# STM32U083xx register map
File version: 1.0
Registers are 32-bit, read-write, reset 0x0 unless marked. A register's access mark holds for its fields unless they carry their own. Offsets are from the block's base; [hi:lo] are bit positions; {n}, {i} and the like mark numbered series.

## OPAMP1 — Operational Amplifier (OPAMP)
Base 0x40007800
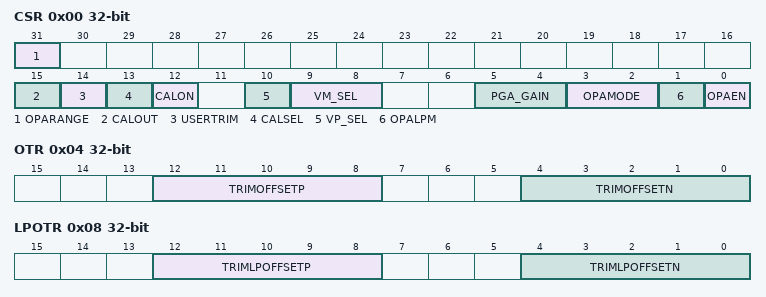
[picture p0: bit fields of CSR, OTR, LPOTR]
0x00 CSR — OPAMP control/status register
  [31] OPARANGE — Operational amplifier range setting
    0=LOW (Power supply range low); 1=HIGH (Power supply range high - recommended for performance purpose)
  [15] CALOUT — Operational amplifier calibration output
  [14] USERTRIM — User trimming enable
    0=FACTORY (OPAMP trimming factors set to factory values); 1=USER (OPAMP trimming factors set to user values)
  [13] CALSEL — Calibration selection
  [12] CALON — Calibration mode enable
    0=FUNCTIONAL (OPAMP functional mode); 1=CALIBRATION (OPAMP calibration mode)
  [10] VP_SEL — Non inverted input selection
    0=NONINVERT_IO0 (OPAMP non inverting input connected to GPIO pin (pin PA0 for OPAMP1)); 1=NONINV_DAC1_CH1 (OPAMP non inverting input connected to DAC1 channel output(channel1 for OPAMP1))
  [9:8] VM_SEL — Inverting input selection
    0=IO0 (OPAMP inverting input connected to GPIO pin (valid also in PGA mode for filtering). Note: OPAMP inverting input is used with OPAMP in mode standalone or PGA with external capacitors for filtering circuit. Otherwise (OPAMP in mode follower), OPAMP inverting input is not used (not connected to GPIO pin).); 2=CONNECT_NO (OPAMP inverting input not externally connected (intended for OPAMP in mode follower or PGA without external capacitors for filtering))
  [5:4] PGA_GAIN — Operational amplifier Programmable amplifier gain value
    0=GAIN_2 (OPAMP PGA gain 2); 1=GAIN_4 (OPAMP PGA gain 4); 2=GAIN_8 (OPAMP PGA gain 8); 3=GAIN_16 (OPAMP PGA gain 16)
  [3:2] OPAMODE — Operational amplifier PGA mode
    0=STANDALONE (OPAMP functional mode, OPAMP operation in standalone); 3=FOLLOWER (OPAMP functional mode, OPAMP operation in follower); 2=PGA (OPAMP functional mode, OPAMP operation in PGA)
  [1] OPALPM — Operational amplifier Low Power Mode
  [0] OPAEN — OPAMP enable
0x04 OTR — OPAMP
  [12:8] TRIMOFFSETP — Trim for PMOS differential pairs
  [4:0] TRIMOFFSETN — Trim for NMOS differential pairs
0x08 LPOTR — OPAMP
  [12:8] TRIMLPOFFSETP — Trim for PMOS differential pairs
  [4:0] TRIMLPOFFSETN — Trim for NMOS differential pairs

## USB_DRD_PMA_BUFF — Universal Serial Bus PacketMemoryArea Buffer Descriptor Table
Base 0x40009800
0x00 TXBD — Transmission buffer address
0x04 RXBD — Reception buffer address

## TAMP — Tamper and backup registers
Base 0x4000B000
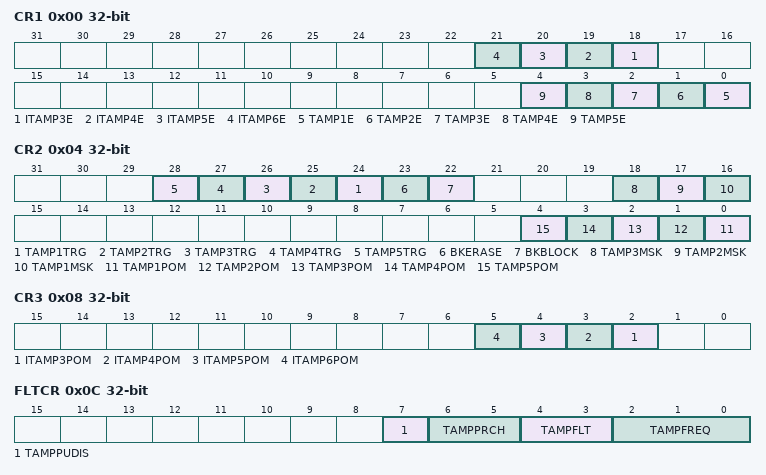
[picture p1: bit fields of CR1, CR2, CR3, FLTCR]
0x00 CR1 — TAMP configuration register 1
  [n+15] ITAMP{n}E (n=3..6), [n-1] TAMP{n}E (n=1..5)
0x04 CR2 — TAMP configuration register 2
  [n+23] TAMP{n}TRG (n=1..5), [23] BKERASE, [22] BKBLOCK, [18] TAMP3MSK, [17] TAMP2MSK, [16] TAMP1MSK, [n-1] TAMP{n}POM (n=1..5)
0x08 CR3 — TAMP configuration register 3
  [n-1] ITAMP{n}POM (n=3..6)
0x0C FLTCR — TAMP filter control register
  [7] TAMPPUDIS
  [6:5] TAMPPRCH
    0=DURATION_1RTCCLK (Tamper pins are pre-charged before sampling during 1 RTCCLK cycle); 1=DURATION_2RTCCLK (Tamper pins are pre-charged before sampling during 2 RTCCLK cycles); 2=DURATION_4RTCCLK (Tamper pins are pre-charged before sampling during 4 RTCCLK cycles); 3=DURATION_8RTCCLK (Tamper pins are pre-charged before sampling during 8 RTCCLK cycles)
  [4:3] TAMPFLT
    0=DISABLE (Tamper filter is disabled); 1=FILTER_2SAMPLE (Tamper is activated after 2 consecutive samples at the active level); 2=FILTER_4SAMPLE (Tamper is activated after 4 consecutive samples at the active level); 3=FILTER_8SAMPLE (Tamper is activated after 8 consecutive samples at the active level.)
  [2:0] TAMPFREQ
    0=SAMPLFREQDIV_32768 (Each of the tamper inputs are sampled with a frequency = RTCCLK / 32768); 1=SAMPLFREQDIV_16384 (Each of the tamper inputs are sampled with a frequency = RTCCLK / 16384); 2=SAMPLFREQDIV_8192 (Each of the tamper inputs are sampled with a frequency = RTCCLK / 8192); 3=SAMPLFREQDIV_4096 (Each of the tamper inputs are sampled with a frequency = RTCCLK / 4096); 4=SAMPLFREQDIV_2048 (Each of the tamper inputs are sampled with a frequency = RTCCLK / 2048); 5=SAMPLFREQDIV_1024 (Each of the tamper inputs are sampled with a frequency = RTCCLK / 1024); 6=SAMPLFREQDIV_512 (Each of the tamper inputs are sampled with a frequency = RTCCLK / 512); 7=SAMPLFREQDIV_256 (Each of the tamper inputs are sampled with a frequency = RTCCLK / 256)
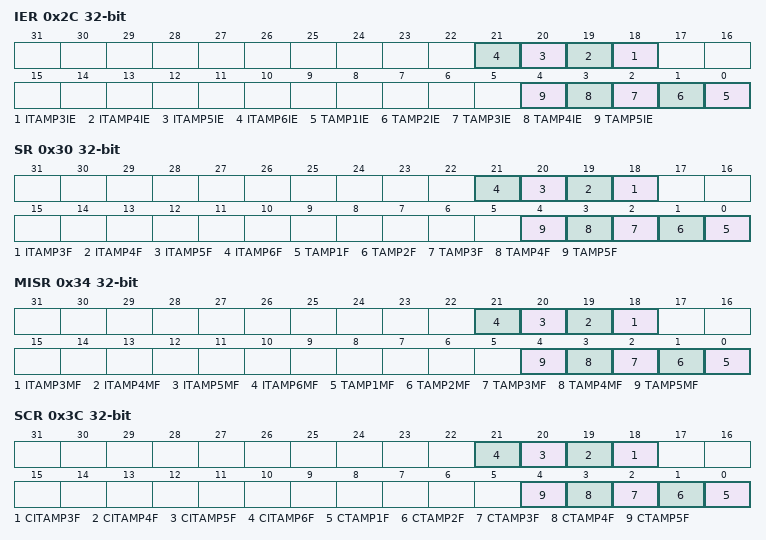
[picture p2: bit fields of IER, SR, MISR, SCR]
0x2C IER — TAMP interrupt enable register
  [n+15] ITAMP{n}IE (n=3..6), [n-1] TAMP{n}IE (n=1..5)
0x30 SR — TAMP status register
  [n+15] ITAMP{n}F (n=3..6), [n-1] TAMP{n}F (n=1..5)
0x34 MISR — TAMP masked interrupt status register
  [n+15] ITAMP{n}MF (n=3..6), [n-1] TAMP{n}MF (n=1..5)
0x3C SCR — TAMP status clear register
  [n+15] CITAMP{n}F (n=3..6), [n-1] CTAMP{n}F (n=1..5)
{0x100+4i} BKP{i}R (i=0..8) — TAMP backup register {i}
